# ATtiny828 device description
Architecture: AVR8; Family: tinyAVR
Registers are 8-bit, access not given, no defined reset value unless marked. A register's access mark holds for its fields unless they carry their own. Offsets are from the block's base; [hi:lo] are bit positions; 'fields as' and 'values as' point back to an identical list.

## AC — Analog Comparator
Instances: AC 0x00
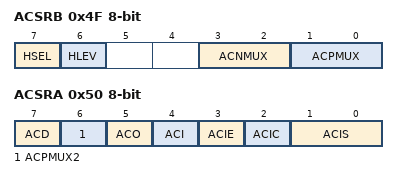
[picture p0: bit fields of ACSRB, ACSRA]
0x4F ACSRB — Analog Comparator Control And Status Register B
  [7] HSEL — Hysteresis Select
  [6] HLEV — Hysteresis Level
  [3:2] ACNMUX — Analog Comparator Negative Input Multiplexer
  [1:0] ACPMUX — Analog Comparator Positive Input Multiplexer Bits 1:0
0x50 ACSRA — Analog Comparator Control And Status Register A
  [7] ACD — Analog Comparator Disable
  [6] ACPMUX2 — Analog Comparator Positive Input Multiplexer Bit 2
  [5] ACO — Analog Compare Output
  [4] ACI — Analog Comparator Interrupt Flag
  [3] ACIE — Analog Comparator Interrupt Enable
  [2] ACIC — Analog Comparator Input Capture Enable
  [1:0] ACIS — Analog Comparator Interrupt Mode Select bits
    0=INTERRUPT_ON_TOGGLE; 2=INTERRUPT_ON_FALLING_EDGE; 3=INTERRUPT_ON_RISING_EDGE

## EXINT — External Interrupts
Instances: EXINT 0x00
0x3B PCIFR — Pin Change Interrupt Flag Register
  [3:0] PCIF — Pin Change Interrupt Flags
0x3C EIFR — External Interrupt Flag Register
  [1:0] INTF — External Interrupt Flags
0x3D EIMSK — External Interrupt Mask Register
  [1:0] INT — External Interrupt Request Enables
0x68 PCICR — Pin Change Interrupt Control Register
  [3:0] PCIE — Pin Change Interrupt Enables
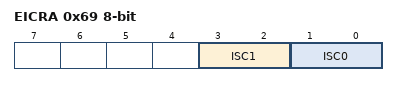
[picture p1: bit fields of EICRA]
0x69 EICRA — External Interrupt Control Register
  [3:2] ISC1 — External Interrupt Sense Control 1 Bits
    0=LOW_LEVEL_OF_INTX; 1=ANY_LOGICAL_CHANGE_OF_INTX; 2=FALLING_EDGE_OF_INTX; 3=RISING_EDGE_OF_INTX
  [1:0] ISC0 — External Interrupt Sense Control 0 Bits
    values as ISC1
0x6B PCMSK0 — Pin Change Mask Register 0
  [7:0] PCINT — Pin Change Enable Masks
0x6C PCMSK1 — Pin Change Mask Register 1
  [7:0] PCINT (bit 8 of the value upward) — Pin Change Enable Masks
0x6D PCMSK2 — Pin Change Mask Register 2
  [7:0] PCINT (bit 16 of the value upward) — Pin Change Enable Masks
0x73 PCMSK3 — Pin Change Mask Register 3
  [3:0] PCINT (bit 24 of the value upward) — Pin Change Enable Masks

## WDT — Watchdog Timer
Instances: WDT 0x00
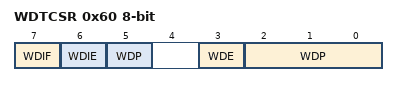
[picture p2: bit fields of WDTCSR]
0x60 WDTCSR — Watchdog Timer Control and Status Register
  [7] WDIF — Watchdog Timer Interrupt Flag
  [6] WDIE — Watchdog Timer Interrupt Enable
  [3] WDE — Watch Dog Enable
  [5,2:0] WDP — Watchdog Timer Prescaler Bits
    0=OSCILLATOR_CYCLES_512_16_MS; 1=OSCILLATOR_CYCLES_1K_32_MS; 2=OSCILLATOR_CYCLES_2K_64_MS; 3=OSCILLATOR_CYCLES_4K_0_125_S; 4=OSCILLATOR_CYCLES_8K_0_25_S; 5=OSCILLATOR_CYCLES_16K_0_5_S; 6=OSCILLATOR_CYCLES_32K_1_0_S; 7=OSCILLATOR_CYCLES_64K_2_0_S; 8=OSCILLATOR_CYCLES_128K_4_0_S; 9=OSCILLATOR_CYCLES_256K_8_0_S

## EEPROM
Instances: EEPROM 0x00
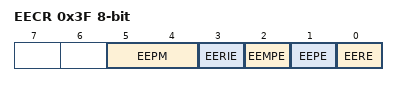
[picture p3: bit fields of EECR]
0x3F EECR — EEPROM Control Register
  [5:4] EEPM — EEPROM Programming Mode Bits
    0=ERASE_AND_WRITE_IN_ONE_OPERATION; 1=ERASE_ONLY; 2=WRITE_ONLY
  [3] EERIE — EEProm Ready Interrupt Enable
  [2] EEMPE — EEPROM Master Write Enable
  [1] EEPE — EEPROM Write Enable
  [0] EERE — EEPROM Read Enable
0x40 EEDR — EEPROM Data Register
0x41 EEAR — EEPROM Read/Write Access
0x41 EEARL — EEPROM Read/Write Access

## TWI — Two Wire Serial Interface
Instances: TWI 0x00
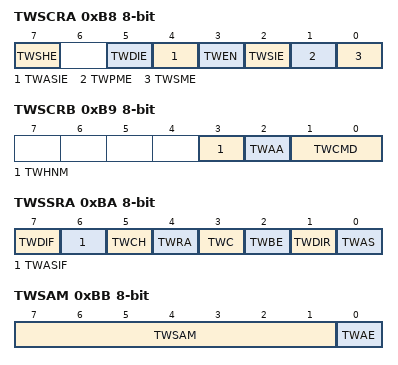
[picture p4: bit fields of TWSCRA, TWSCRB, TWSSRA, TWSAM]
0xB8 TWSCRA — TWI Slave Control Register A
  [7] TWSHE — TWI SDA Hold Time Enable
  [5] TWDIE — TWI Data Interrupt Enable
  [4] TWASIE — TWI Address/Stop Interrupt Enable
  [3] TWEN — Two-Wire Interface Enable
  [2] TWSIE — TWI Stop Interrupt Enable
  [1] TWPME — TWI Promiscuous Mode Enable
  [0] TWSME — TWI Smart Mode Enable
0xB9 TWSCRB — TWI Slave Control Register B
  [3] TWHNM — TWI High Noise Mode
  [2] TWAA — TWI Acknowledge Action
  [1:0] TWCMD
0xBA TWSSRA — TWI Slave Status Register A
  [7] TWDIF — TWI Data Interrupt Flag.
  [6] TWASIF — TWI Address/Stop Interrupt Flag
  [5] TWCH — TWI Clock Hold
  [4] TWRA — TWI Receive Acknowledge
  [3] TWC — TWI Collision
  [2] TWBE — TWI Bus Error
  [1] TWDIR — TWI Read/Write Direction
  [0] TWAS — TWI Address or Stop
0xBB TWSAM — TWI Slave Address Mask Register
  [7:1] TWSAM (bit 1 of the value upward) — TWI Address Mask Bits
  [0] TWAE — TWI Address Enable
0xBC TWSA — TWI Slave Address Register
0xBD TWSD — TWI Slave Data Register
  [7:0] TWSD — TWI slave data bit

## USART
Instances: USART 0x00
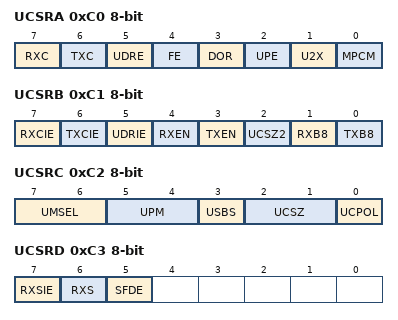
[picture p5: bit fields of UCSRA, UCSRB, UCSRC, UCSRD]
0xC0 UCSRA — USART Control and Status Register A
  [7] RXC ro — USART Receive Complete
  [6] TXC — USART Transmit Complete
  [5] UDRE ro — USART Data Register Empty
  [4] FE ro — Framing Error
  [3] DOR ro — Data Overrun
  [2] UPE ro — Parity Error
  [1] U2X — Double the USART transmission speed
  [0] MPCM — Multi-processor Communication Mode
0xC1 UCSRB — USART Control and Status Register B
  [7] RXCIE — RX Complete Interrupt Enable
  [6] TXCIE — TX Complete Interrupt Enable
  [5] UDRIE — USART Data register Empty Interrupt Enable
  [4] RXEN — Receiver Enable
  [3] TXEN — Transmitter Enable
  [2] UCSZ2 — Character Size
  [1] RXB8 — Receive Data Bit 8
  [0] TXB8 — Transmit Data Bit 8
0xC2 UCSRC — USART Control and Status Register C
  [7:6] UMSEL — USART Mode Select
    0=ASYNCHRONOUS_OPERATION; 1=SYNCHRONOUS_OPERATION
  [5:4] UPM — Parity Mode Bits
    0=DISABLED; 2=ENABLED_EVEN_PARITY; 3=ENABLED_ODD_PARITY
  [3] USBS — Stop Bit Select
    0=1_BIT; 1=2_BIT
  [2:1] UCSZ — Character Size
  [0] UCPOL — Clock Polarity
0xC3 UCSRD — USART Control and Status Register D
  [7] RXSIE — USART RX Start Interrupt Enable
  [6] RXS — USART RX Start Flag
  [5] SFDE — USART RX Start Frame Detection Enable
0xC4 UBRR 16-bit bits used 11:0 — USART Baud Rate Register Bytes
0xC6 UDR — USART I/O Data Register
